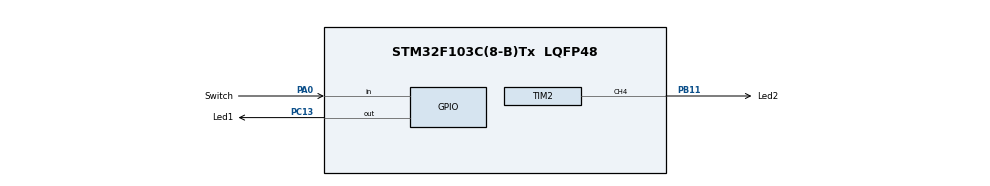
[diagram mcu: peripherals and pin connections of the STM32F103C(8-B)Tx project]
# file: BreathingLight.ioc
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Mcu.Family=STM32F1
Mcu.Name=STM32F103C(8-B)Tx
Mcu.Package=LQFP48
NVIC.PriorityGroup=NVIC_PRIORITYGROUP_4
PA0-WKUP.GPIO_Label=Switch
PA0-WKUP.Signal=GPIO_Input
PB11.GPIO_Label=Led2
PB11.GPIO_Speed=GPIO_SPEED_FREQ_MEDIUM
PB11.Signal=S_TIM2_CH4
PC13-TAMPER-RTC.GPIO_Label=Led1
PC13-TAMPER-RTC.GPIO_Speed=GPIO_SPEED_FREQ_MEDIUM
PC13-TAMPER-RTC.PinState=GPIO_PIN_SET
PC13-TAMPER-RTC.Signal=GPIO_Output
ProjectManager.HeapSize=0x200
ProjectManager.StackSize=0x400
ProjectManager.TargetToolchain=MDK-ARM V5
RCC.APB1Freq_Value=8000000
RCC.APB2Freq_Value=8000000
SH.S_TIM2_CH4.0=TIM2_CH4,PWM Generation4 CH4
TIM2.Channel-PWM\ Generation4\ CH4=TIM_CHANNEL_4
VP_SYS_VS_ND.Mode=No_Debug
board=custom

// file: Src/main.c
/* USER CODE BEGIN Header */
/**
  ******************************************************************************
  * @file           : main.c
  * @brief          : Main program body
  ******************************************************************************
  * @attention
  *
  * <h2><center>&copy; Copyright (c) 2020 STMicroelectronics.
  * All rights reserved.</center></h2>
  *
  * This software component is licensed by ST under BSD 3-Clause license,
  * the "License"; You may not use this file except in compliance with the
  * License. You may obtain a copy of the License at:
  *                        opensource.org/licenses/BSD-3-Clause
  *
  ******************************************************************************
  */
/* USER CODE END Header */

#include "main.h"

TIM_HandleTypeDef htim2;

void SystemClock_Config(void);
static void MX_GPIO_Init(void);
static void MX_TIM2_Init(void);

int main(void)
{

  /* MCU Configuration--------------------------------------------------------*/

  /* Reset of all peripherals, Initializes the Flash interface and the Systick. */
  HAL_Init();

  /* Configure the system clock */
  SystemClock_Config();

  /* Initialize all configured peripherals */
  MX_GPIO_Init();
  MX_TIM2_Init();
  /* USER CODE BEGIN 2 */
  HAL_TIM_Base_Start(&htim2);
  HAL_TIM_PWM_Init(&htim2);
  HAL_TIM_PWM_Start(&htim2, TIM_CHANNEL_4);
  /* USER CODE END 2 */

  /* Infinite loop */
  while (1)
  {
    if (HAL_GPIO_ReadPin(Switch_GPIO_Port, Switch_Pin) == GPIO_PIN_RESET)
    {
      HAL_GPIO_WritePin(Led1_GPIO_Port, Led1_Pin, GPIO_PIN_RESET);
    }
    else
    {
      HAL_GPIO_WritePin(Led1_GPIO_Port, Led1_Pin, GPIO_PIN_SET);
    }
    HAL_Delay(10);
    /*Task2&3*/
    int pulse = 0;
    for (pulse = 0; pulse < 400; pulse = pulse + 1)
    {
      TIM2->CCR4 = pulse;
      HAL_Delay(2500);
    }
    for (pulse = 400; pulse > 0; pulse = pulse - 1)
    {
      TIM2->CCR4 = pulse;
      HAL_Delay(2500);
    }

  }
}

void SystemClock_Config(void)
{
  RCC_OscInitTypeDef RCC_OscInitStruct = {0};
  RCC_ClkInitTypeDef RCC_ClkInitStruct = {0};

  /** Initializes the CPU, AHB and APB busses clocks
  */
  RCC_OscInitStruct.OscillatorType = RCC_OSCILLATORTYPE_HSI;
  RCC_OscInitStruct.HSIState = RCC_HSI_ON;
  RCC_OscInitStruct.HSICalibrationValue = RCC_HSICALIBRATION_DEFAULT;
  RCC_OscInitStruct.PLL.PLLState = RCC_PLL_NONE;
  if (HAL_RCC_OscConfig(&RCC_OscInitStruct) != HAL_OK)
  {
    Error_Handler();
  }
  /** Initializes the CPU, AHB and APB busses clocks
  */
  RCC_ClkInitStruct.ClockType = RCC_CLOCKTYPE_HCLK | RCC_CLOCKTYPE_SYSCLK | RCC_CLOCKTYPE_PCLK1 | RCC_CLOCKTYPE_PCLK2;
  RCC_ClkInitStruct.SYSCLKSource = RCC_SYSCLKSOURCE_HSI;
  RCC_ClkInitStruct.AHBCLKDivider = RCC_SYSCLK_DIV1;
  RCC_ClkInitStruct.APB1CLKDivider = RCC_HCLK_DIV1;
  RCC_ClkInitStruct.APB2CLKDivider = RCC_HCLK_DIV1;

  if (HAL_RCC_ClockConfig(&RCC_ClkInitStruct, FLASH_LATENCY_0) != HAL_OK)
  {
    Error_Handler();
  }
}

static void MX_TIM2_Init(void)
{

  TIM_MasterConfigTypeDef sMasterConfig = {0};
  TIM_OC_InitTypeDef sConfigOC = {0};

  htim2.Instance = TIM2;
  htim2.Init.Prescaler = 19;
  htim2.Init.CounterMode = TIM_COUNTERMODE_UP;
  htim2.Init.Period = 400;
  htim2.Init.ClockDivision = TIM_CLOCKDIVISION_DIV1;
  htim2.Init.AutoReloadPreload = TIM_AUTORELOAD_PRELOAD_DISABLE;
  if (HAL_TIM_PWM_Init(&htim2) != HAL_OK)
  {
    Error_Handler();
  }
  sMasterConfig.MasterOutputTrigger = TIM_TRGO_RESET;
  sMasterConfig.MasterSlaveMode = TIM_MASTERSLAVEMODE_DISABLE;
  if (HAL_TIMEx_MasterConfigSynchronization(&htim2, &sMasterConfig) != HAL_OK)
  {
    Error_Handler();
  }
  sConfigOC.OCMode = TIM_OCMODE_PWM1;
  sConfigOC.Pulse = 0;
  sConfigOC.OCPolarity = TIM_OCPOLARITY_HIGH;
  sConfigOC.OCFastMode = TIM_OCFAST_DISABLE;
  if (HAL_TIM_PWM_ConfigChannel(&htim2, &sConfigOC, TIM_CHANNEL_4) != HAL_OK)
  {
    Error_Handler();
  }
  HAL_TIM_MspPostInit(&htim2);
}

static void MX_GPIO_Init(void)
{
  GPIO_InitTypeDef GPIO_InitStruct = {0};

  /* GPIO Ports Clock Enable */
  __HAL_RCC_GPIOC_CLK_ENABLE();
  __HAL_RCC_GPIOA_CLK_ENABLE();
  __HAL_RCC_GPIOB_CLK_ENABLE();

  /*Configure GPIO pin Output Level */
  HAL_GPIO_WritePin(Led1_GPIO_Port, Led1_Pin, GPIO_PIN_SET);

  /*Configure GPIO pin : Led1_Pin */
  GPIO_InitStruct.Pin = Led1_Pin;
  GPIO_InitStruct.Mode = GPIO_MODE_OUTPUT_PP;
  GPIO_InitStruct.Pull = GPIO_NOPULL;
  GPIO_InitStruct.Speed = GPIO_SPEED_FREQ_MEDIUM;
  HAL_GPIO_Init(Led1_GPIO_Port, &GPIO_InitStruct);

  /*Configure GPIO pin : Switch_Pin */
  GPIO_InitStruct.Pin = Switch_Pin;
  GPIO_InitStruct.Mode = GPIO_MODE_INPUT;
  GPIO_InitStruct.Pull = GPIO_NOPULL;
  HAL_GPIO_Init(Switch_GPIO_Port, &GPIO_InitStruct);
}

void Error_Handler(void)
{
}

/************************ (C) COPYRIGHT STMicroelectronics *****END OF FILE****/
